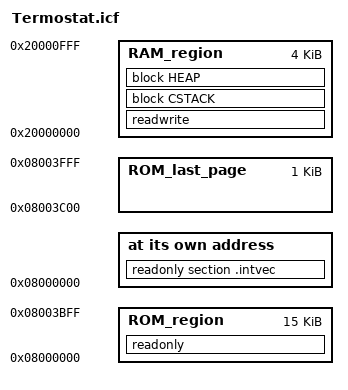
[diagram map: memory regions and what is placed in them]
/*###ICF### Section handled by ICF editor, don't touch! ****/
/*-Editor annotation file-*/
/* IcfEditorFile="$TOOLKIT_DIR$\config\ide\IcfEditor\cortex_v1_0.xml" */
/*-Specials-*/
define symbol __ICFEDIT_intvec_start__ = 0x08000000;    /* начало векторов */
/*-Memory Regions-*/
define symbol __ICFEDIT_region_ROM_start__      = 0x08000000;
define symbol __ICFEDIT_region_ROM_end__        = 0x08003BFF;  /* до последней страницы */
define symbol __ICFEDIT_region_ROM_last_start__ = 0x08003C00;  /* начало последней страницы */
define symbol __ICFEDIT_region_ROM_last_end__   = 0x08003FFF;  /* конец последней страницы */
define symbol __ICFEDIT_region_RAM_start__      = 0x20000000;
define symbol __ICFEDIT_region_RAM_end__        = 0x20000FFF;
/*-Sizes-*/
define symbol __ICFEDIT_size_cstack__ = 0x400;
define symbol __ICFEDIT_size_heap__   = 0x0;
/**** End of ICF editor section. ###ICF###*/

define memory mem with size = 4G;
define region ROM_region   = mem:[from __ICFEDIT_region_ROM_start__   to __ICFEDIT_region_ROM_end__];
define region ROM_last_page = mem:[from __ICFEDIT_region_ROM_last_start__ to __ICFEDIT_region_ROM_last_end__];
define region RAM_region   = mem:[from __ICFEDIT_region_RAM_start__   to __ICFEDIT_region_RAM_end__];

define block CSTACK    with alignment = 8, size = __ICFEDIT_size_cstack__   { };
define block HEAP      with alignment = 8, size = __ICFEDIT_size_heap__     { };

initialize by copy { readwrite };

place at address mem:__ICFEDIT_intvec_start__ { readonly section .intvec };
place in ROM_region   { readonly };
place in RAM_region   { readwrite,
                        block CSTACK, block HEAP };
/* Последняя страница не используется линкером, оставлена свободной */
